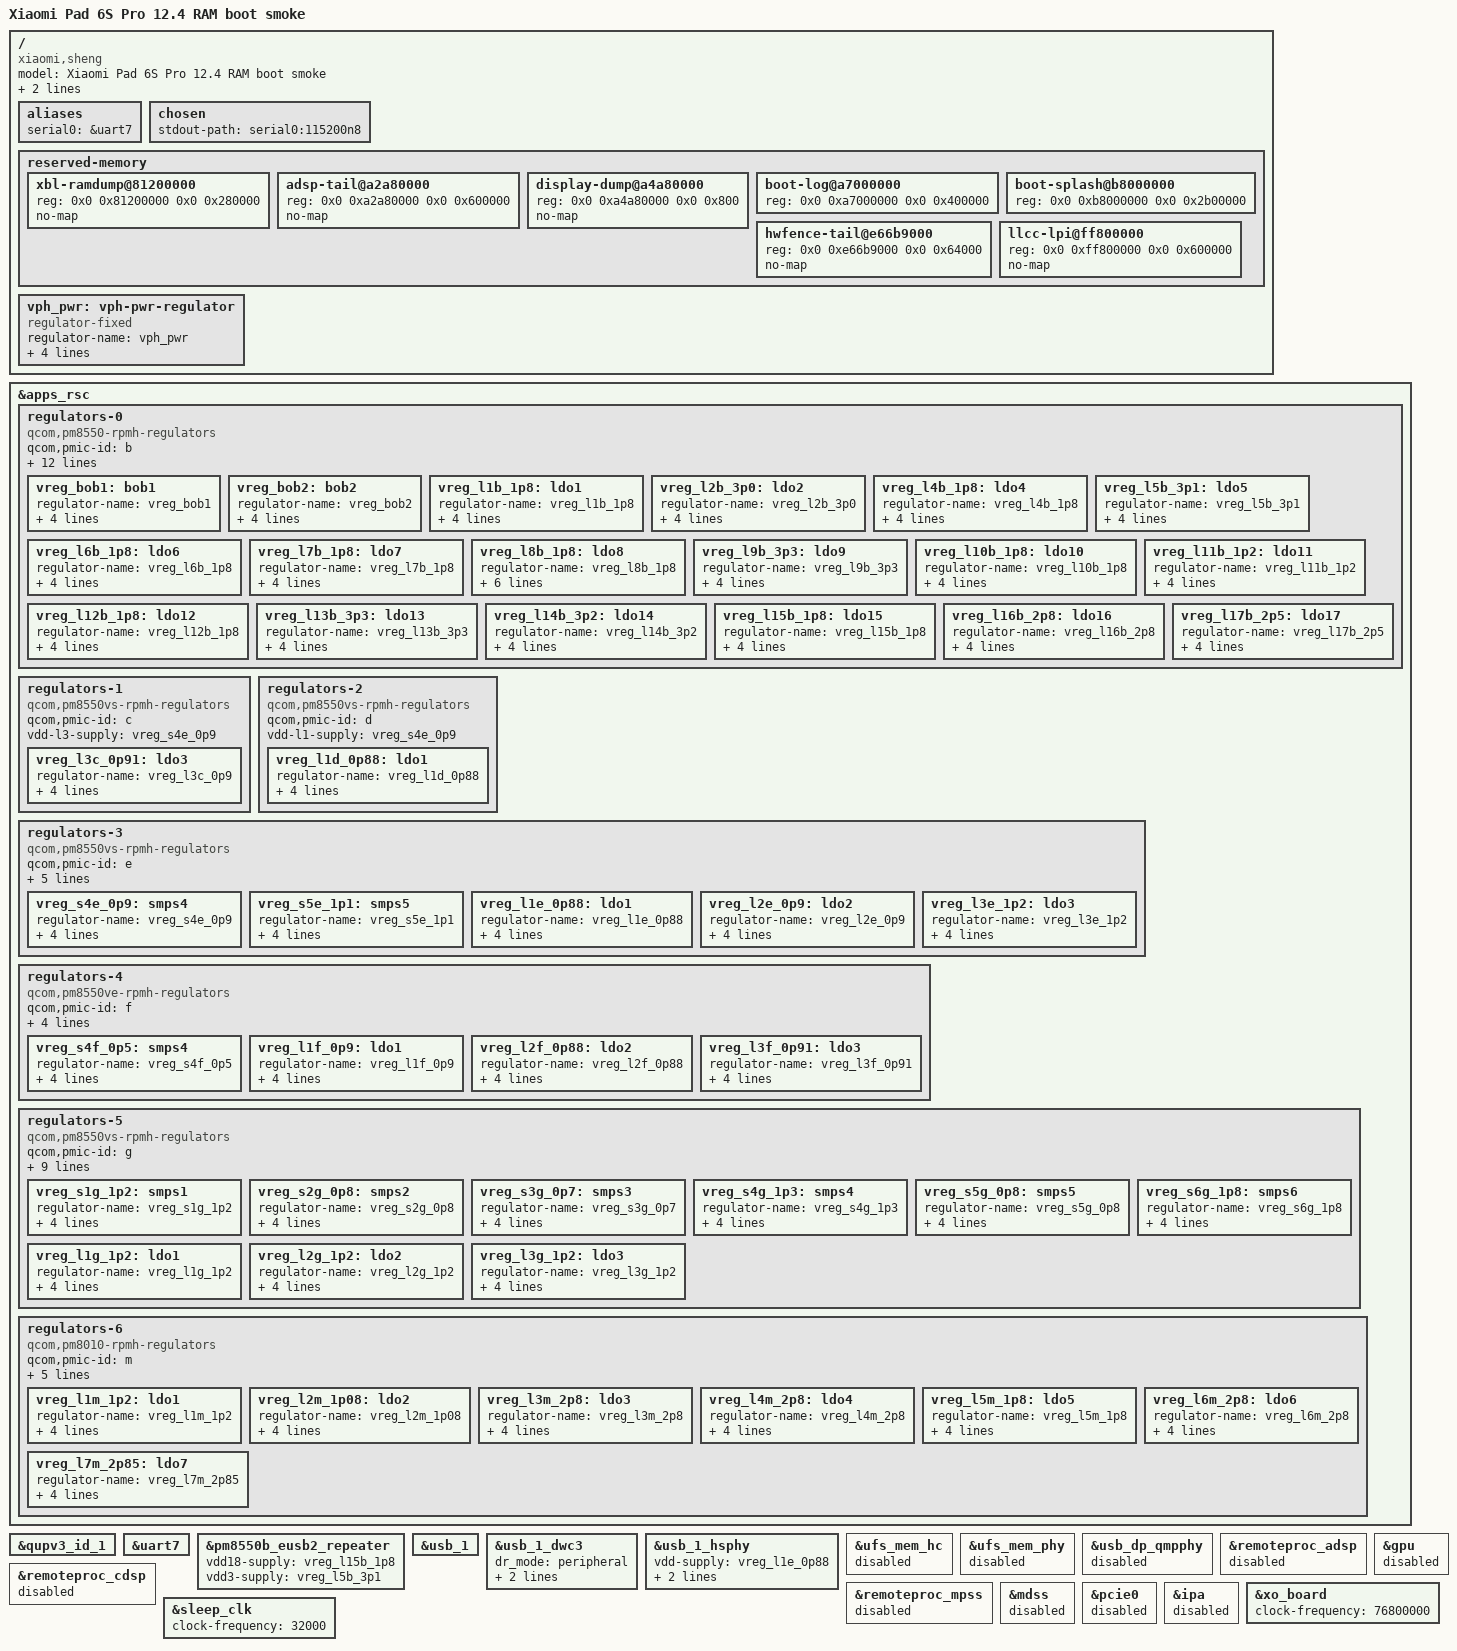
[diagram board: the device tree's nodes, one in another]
// SPDX-License-Identifier: BSD-3-Clause
/*
 * Board regulator data derived from map220v sheng-6.12
 * Copyright (c) 2024, map220v <map220v300@gmail.com>
 */

/dts-v1/;

#include <dt-bindings/arm/qcom,ids.h>
#include <dt-bindings/regulator/qcom,rpmh-regulator.h>
#include "sm8550.dtsi"
#include "pm8010.dtsi"
#include "pm8550.dtsi"
#include "pm8550b.dtsi"
#define PMK8550VE_SID 5
#include "pm8550ve.dtsi"
#include "pm8550vs.dtsi"
#include "pmk8550.dtsi"

/ {
	model = "Xiaomi Pad 6S Pro 12.4 RAM boot smoke";
	compatible = "xiaomi,sheng", "qcom,sm8550";
	qcom,msm-id = <536 0x20000>;
	qcom,board-id = <0x10008 0>;

	aliases {
		serial0 = &uart7;
	};

	chosen {
		stdout-path = "serial0:115200n8";
	};

	/* 保留固件仍占用的内存，避免分配给内核 */
	reserved-memory {
		xbl-ramdump@81200000 {
			reg = <0x0 0x81200000 0x0 0x280000>;
			no-map;
		};

		adsp-tail@a2a80000 {
			reg = <0x0 0xa2a80000 0x0 0x600000>;
			no-map;
		};

		display-dump@a4a80000 {
			reg = <0x0 0xa4a80000 0x0 0x800>;
			no-map;
		};

		boot-log@a7000000 {
			reg = <0x0 0xa7000000 0x0 0x400000>;
		};

		boot-splash@b8000000 {
			reg = <0x0 0xb8000000 0x0 0x2b00000>;
		};

		hwfence-tail@e66b9000 {
			reg = <0x0 0xe66b9000 0x0 0x64000>;
			no-map;
		};

		llcc-lpi@ff800000 {
			reg = <0x0 0xff800000 0x0 0x600000>;
			no-map;
		};
	};

	/* 定义板级主电源输入 */
	vph_pwr: vph-pwr-regulator {
		compatible = "regulator-fixed";
		regulator-name = "vph_pwr";
		regulator-min-microvolt = <3700000>;
		regulator-max-microvolt = <3700000>;

		regulator-always-on;
		regulator-boot-on;
	};
};

/* 使用原板级电压数据供给 USB 及串口依赖 */
&apps_rsc {
	regulators-0 {
		compatible = "qcom,pm8550-rpmh-regulators";
		qcom,pmic-id = "b";

		vdd-bob1-supply = <&vph_pwr>;
		vdd-bob2-supply = <&vph_pwr>;
		vdd-l1-l4-l10-supply = <&vreg_s6g_1p8>;
		vdd-l2-l13-l14-supply = <&vreg_bob1>;
		vdd-l3-supply = <&vreg_s4g_1p3>;
		vdd-l5-l16-supply = <&vreg_bob1>;
		vdd-l6-l7-supply = <&vreg_bob1>;
		vdd-l8-l9-supply = <&vreg_bob1>;
		vdd-l11-supply = <&vreg_s4g_1p3>;
		vdd-l12-supply = <&vreg_s6g_1p8>;
		vdd-l15-supply = <&vreg_s6g_1p8>;
		vdd-l17-supply = <&vreg_bob2>;

		vreg_bob1: bob1 {
			regulator-name = "vreg_bob1";
			regulator-min-microvolt = <3296000>;
			regulator-max-microvolt = <3960000>;
			regulator-initial-mode = <RPMH_REGULATOR_MODE_HPM>;
		};

		/* Xiaomi change for Camera Modules */
		vreg_bob2: bob2 {
			regulator-name = "vreg_bob2";
			regulator-min-microvolt = <2704000>;
			regulator-max-microvolt = <3296000>;
			regulator-initial-mode = <RPMH_REGULATOR_MODE_HPM>;
		};

		vreg_l1b_1p8: ldo1 {
			regulator-name = "vreg_l1b_1p8";
			regulator-min-microvolt = <1800000>;
			regulator-max-microvolt = <1800000>;
			regulator-initial-mode = <RPMH_REGULATOR_MODE_HPM>;
		};

		vreg_l2b_3p0: ldo2 {
			regulator-name = "vreg_l2b_3p0";
			regulator-min-microvolt = <3008000>;
			regulator-max-microvolt = <3008000>;
			regulator-initial-mode = <RPMH_REGULATOR_MODE_HPM>;
		};

		vreg_l4b_1p8: ldo4 {
			regulator-name = "vreg_l4b_1p8";
			regulator-min-microvolt = <1800000>;
			regulator-max-microvolt = <1800000>;
			regulator-initial-mode = <RPMH_REGULATOR_MODE_HPM>;
		};

		vreg_l5b_3p1: ldo5 {
			regulator-name = "vreg_l5b_3p1";
			regulator-min-microvolt = <3104000>;
			regulator-max-microvolt = <3104000>;
			regulator-initial-mode = <RPMH_REGULATOR_MODE_HPM>;
		};

		/* Xiaomi change for Nanosic WN803x */
		vreg_l6b_1p8: ldo6 {
			regulator-name = "vreg_l6b_1p8";
			regulator-min-microvolt = <1800000>;
			regulator-max-microvolt = <1800000>;
			regulator-initial-mode = <RPMH_REGULATOR_MODE_HPM>;
		};

		/* Xiaomi change for Camera Modules */
		vreg_l7b_1p8: ldo7 {
			regulator-name = "vreg_l7b_1p8";
			regulator-min-microvolt = <1800000>;
			regulator-max-microvolt = <1800000>;
			regulator-initial-mode = <RPMH_REGULATOR_MODE_HPM>;
		};

		/* Xiaomi change for Semtech SX9371 */
		vreg_l8b_1p8: ldo8 {
			regulator-name = "vreg_l8b_1p8";
			regulator-min-microvolt = <1800000>;
			regulator-max-microvolt = <1800000>;
			regulator-initial-mode = <RPMH_REGULATOR_MODE_HPM>;
			regulator-always-on;
			regulator-boot-on;
		};

		/* Xiaomi change for FPC1552 */
		vreg_l9b_3p3: ldo9 {
			regulator-name = "vreg_l9b_3p3";
			regulator-min-microvolt = <3296000>;
			regulator-max-microvolt = <3296000>;
			regulator-initial-mode = <RPMH_REGULATOR_MODE_HPM>;
		};

		vreg_l10b_1p8: ldo10 {
			regulator-name = "vreg_l10b_1p8";
			regulator-min-microvolt = <1800000>;
			regulator-max-microvolt = <1800000>;
			regulator-initial-mode = <RPMH_REGULATOR_MODE_HPM>;
		};

		vreg_l11b_1p2: ldo11 {
			regulator-name = "vreg_l11b_1p2";
			regulator-min-microvolt = <1200000>;
			regulator-max-microvolt = <1504000>;
			regulator-initial-mode = <RPMH_REGULATOR_MODE_HPM>;
		};

		vreg_l12b_1p8: ldo12 {
			regulator-name = "vreg_l12b_1p8";
			regulator-min-microvolt = <1800000>;
			regulator-max-microvolt = <1800000>;
			regulator-initial-mode = <RPMH_REGULATOR_MODE_HPM>;
		};

		/* Xiaomi change for Nanosic WN803x */
		vreg_l13b_3p3: ldo13 {
			regulator-name = "vreg_l13b_3p3";
			regulator-min-microvolt = <3296000>;
			regulator-max-microvolt = <3296000>;
			regulator-initial-mode = <RPMH_REGULATOR_MODE_HPM>;
		};

		vreg_l14b_3p2: ldo14 {
			regulator-name = "vreg_l14b_3p2";
			regulator-min-microvolt = <3200000>;
			regulator-max-microvolt = <3200000>;
			regulator-initial-mode = <RPMH_REGULATOR_MODE_HPM>;
		};

		vreg_l15b_1p8: ldo15 {
			regulator-name = "vreg_l15b_1p8";
			regulator-min-microvolt = <1800000>;
			regulator-max-microvolt = <1800000>;
			regulator-initial-mode = <RPMH_REGULATOR_MODE_HPM>;
		};

		vreg_l16b_2p8: ldo16 {
			regulator-name = "vreg_l16b_2p8";
			regulator-min-microvolt = <2800000>;
			regulator-max-microvolt = <2800000>;
			regulator-initial-mode = <RPMH_REGULATOR_MODE_HPM>;
		};

		vreg_l17b_2p5: ldo17 {
			regulator-name = "vreg_l17b_2p5";
			regulator-min-microvolt = <2504000>;
			regulator-max-microvolt = <2504000>;
			regulator-initial-mode = <RPMH_REGULATOR_MODE_HPM>;
		};
	};

	regulators-1 {
		compatible = "qcom,pm8550vs-rpmh-regulators";
		qcom,pmic-id = "c";

		vdd-l3-supply = <&vreg_s4e_0p9>;

		vreg_l3c_0p91: ldo3 {
			regulator-name = "vreg_l3c_0p9";
			regulator-min-microvolt = <880000>;
			regulator-max-microvolt = <912000>;
			regulator-initial-mode = <RPMH_REGULATOR_MODE_HPM>;
		};
	};

	regulators-2 {
		compatible = "qcom,pm8550vs-rpmh-regulators";
		qcom,pmic-id = "d";

		vdd-l1-supply = <&vreg_s4e_0p9>;

		vreg_l1d_0p88: ldo1 {
			regulator-name = "vreg_l1d_0p88";
			regulator-min-microvolt = <880000>;
			regulator-max-microvolt = <920000>;
			regulator-initial-mode = <RPMH_REGULATOR_MODE_HPM>;
		};
	};

	regulators-3 {
		compatible = "qcom,pm8550vs-rpmh-regulators";
		qcom,pmic-id = "e";

		vdd-l1-supply = <&vreg_s4e_0p9>;
		vdd-l2-supply = <&vreg_s4e_0p9>;
		vdd-l3-supply = <&vreg_s4g_1p3>;
		vdd-s4-supply = <&vph_pwr>;
		vdd-s5-supply = <&vph_pwr>;

		vreg_s4e_0p9: smps4 {
			regulator-name = "vreg_s4e_0p9";
			regulator-min-microvolt = <904000>;
			regulator-max-microvolt = <984000>;
			regulator-initial-mode = <RPMH_REGULATOR_MODE_HPM>;
		};

		vreg_s5e_1p1: smps5 {
			regulator-name = "vreg_s5e_1p1";
			regulator-min-microvolt = <1080000>;
			regulator-max-microvolt = <1120000>;
			regulator-initial-mode = <RPMH_REGULATOR_MODE_HPM>;
		};

		vreg_l1e_0p88: ldo1 {
			regulator-name = "vreg_l1e_0p88";
			regulator-min-microvolt = <880000>;
			regulator-max-microvolt = <880000>;
			regulator-initial-mode = <RPMH_REGULATOR_MODE_HPM>;
		};

		vreg_l2e_0p9: ldo2 {
			regulator-name = "vreg_l2e_0p9";
			regulator-min-microvolt = <904000>;
			regulator-max-microvolt = <970000>;
			regulator-initial-mode = <RPMH_REGULATOR_MODE_HPM>;
		};

		vreg_l3e_1p2: ldo3 {
			regulator-name = "vreg_l3e_1p2";
			regulator-min-microvolt = <1200000>;
			regulator-max-microvolt = <1200000>;
			regulator-initial-mode = <RPMH_REGULATOR_MODE_HPM>;
		};
	};

	regulators-4 {
		compatible = "qcom,pm8550ve-rpmh-regulators";
		qcom,pmic-id = "f";

		vdd-l1-supply = <&vreg_s4e_0p9>;
		vdd-l2-supply = <&vreg_s4e_0p9>;
		vdd-l3-supply = <&vreg_s4e_0p9>;
		vdd-s4-supply = <&vph_pwr>;

		vreg_s4f_0p5: smps4 {
			regulator-name = "vreg_s4f_0p5";
			regulator-min-microvolt = <500000>;
			regulator-max-microvolt = <700000>;
			regulator-initial-mode = <RPMH_REGULATOR_MODE_HPM>;
		};

		vreg_l1f_0p9: ldo1 {
			regulator-name = "vreg_l1f_0p9";
			regulator-min-microvolt = <912000>;
			regulator-max-microvolt = <912000>;
			regulator-initial-mode = <RPMH_REGULATOR_MODE_HPM>;
		};

		vreg_l2f_0p88: ldo2 {
			regulator-name = "vreg_l2f_0p88";
			regulator-min-microvolt = <880000>;
			regulator-max-microvolt = <912000>;
			regulator-initial-mode = <RPMH_REGULATOR_MODE_HPM>;
		};

		vreg_l3f_0p91: ldo3 {
			regulator-name = "vreg_l3f_0p91";
			regulator-min-microvolt = <880000>;
			regulator-max-microvolt = <912000>;
			regulator-initial-mode = <RPMH_REGULATOR_MODE_HPM>;
		};
	};

	regulators-5 {
		compatible = "qcom,pm8550vs-rpmh-regulators";
		qcom,pmic-id = "g";

		vdd-l1-supply = <&vreg_s4g_1p3>;
		vdd-l2-supply = <&vreg_s4g_1p3>;
		vdd-l3-supply = <&vreg_s4g_1p3>;
		vdd-s1-supply = <&vph_pwr>;
		vdd-s2-supply = <&vph_pwr>;
		vdd-s3-supply = <&vph_pwr>;
		vdd-s4-supply = <&vph_pwr>;
		vdd-s5-supply = <&vph_pwr>;
		vdd-s6-supply = <&vph_pwr>;

		vreg_s1g_1p2: smps1 {
			regulator-name = "vreg_s1g_1p2";
			regulator-min-microvolt = <1200000>;
			regulator-max-microvolt = <1300000>;
			regulator-initial-mode = <RPMH_REGULATOR_MODE_HPM>;
		};

		vreg_s2g_0p8: smps2 {
			regulator-name = "vreg_s2g_0p8";
			regulator-min-microvolt = <800000>;
			regulator-max-microvolt = <1000000>;
			regulator-initial-mode = <RPMH_REGULATOR_MODE_HPM>;
		};

		/* Xiaomi change for Display Panel */
		vreg_s3g_0p7: smps3 {
			regulator-name = "vreg_s3g_0p7";
			regulator-min-microvolt = <600000>;
			regulator-max-microvolt = <1900000>; //2004000
			regulator-initial-mode = <RPMH_REGULATOR_MODE_HPM>;
		};

		/* Xiaomi change for Camera Modules */
		vreg_s4g_1p3: smps4 {
			regulator-name = "vreg_s4g_1p3";
			regulator-min-microvolt = <1256000>;
			regulator-max-microvolt = <1408000>;
			regulator-initial-mode = <RPMH_REGULATOR_MODE_HPM>;
		};

		vreg_s5g_0p8: smps5 {
			regulator-name = "vreg_s5g_0p8";
			regulator-min-microvolt = <500000>;
			regulator-max-microvolt = <1004000>;
			regulator-initial-mode = <RPMH_REGULATOR_MODE_HPM>;
		};

		vreg_s6g_1p8: smps6 {
			regulator-name = "vreg_s6g_1p8";
			regulator-min-microvolt = <1800000>;
			regulator-max-microvolt = <2000000>;
			regulator-initial-mode = <RPMH_REGULATOR_MODE_HPM>;
		};

		vreg_l1g_1p2: ldo1 {
			regulator-name = "vreg_l1g_1p2";
			regulator-min-microvolt = <1200000>;
			regulator-max-microvolt = <1200000>;
			regulator-initial-mode = <RPMH_REGULATOR_MODE_HPM>;
		};

		vreg_l2g_1p2: ldo2 {
			regulator-name = "vreg_l2g_1p2";
			regulator-min-microvolt = <1200000>;
			regulator-max-microvolt = <1200000>;
			regulator-initial-mode = <RPMH_REGULATOR_MODE_HPM>;
		};

		vreg_l3g_1p2: ldo3 {
			regulator-name = "vreg_l3g_1p2";
			regulator-min-microvolt = <1200000>;
			regulator-max-microvolt = <1200000>;
			regulator-initial-mode = <RPMH_REGULATOR_MODE_HPM>;
		};
	};

	regulators-6 {
		compatible = "qcom,pm8010-rpmh-regulators";
		qcom,pmic-id = "m";

		vdd-l1-l2-supply = <&vreg_s4g_1p3>;
		vdd-l3-l4-supply = <&vreg_bob2>;
		vdd-l5-supply = <&vreg_s6g_1p8>;
		vdd-l6-supply = <&vreg_s6g_1p8>;
		vdd-l7-supply = <&vreg_bob1>;

		/* Xiaomi change for Camera Modules */
		vreg_l1m_1p2: ldo1 {
			regulator-name = "vreg_l1m_1p2";
			regulator-min-microvolt = <1200000>;
			regulator-max-microvolt = <1200000>;
			regulator-initial-mode = <RPMH_REGULATOR_MODE_HPM>;
		};

		/* Xiaomi change for Camera Modules */
		vreg_l2m_1p08: ldo2 {
			regulator-name = "vreg_l2m_1p08";
			regulator-min-microvolt = <1080000>;
			regulator-max-microvolt = <1080000>;
			regulator-initial-mode = <RPMH_REGULATOR_MODE_HPM>;
		};

		vreg_l3m_2p8: ldo3 {
			regulator-name = "vreg_l3m_2p8";
			regulator-min-microvolt = <2800000>;
			regulator-max-microvolt = <2800000>;
			regulator-initial-mode = <RPMH_REGULATOR_MODE_HPM>;
		};

		vreg_l4m_2p8: ldo4 {
			regulator-name = "vreg_l4m_2p8";
			regulator-min-microvolt = <2800000>;
			regulator-max-microvolt = <2800000>;
			regulator-initial-mode = <RPMH_REGULATOR_MODE_HPM>;
		};

		vreg_l5m_1p8: ldo5 {
			regulator-name = "vreg_l5m_1p8";
			regulator-min-microvolt = <1800000>;
			regulator-max-microvolt = <1800000>;
			regulator-initial-mode = <RPMH_REGULATOR_MODE_HPM>;
		};

		/* Xiaomi change for Camera Modules */
		vreg_l6m_2p8: ldo6 {
			regulator-name = "vreg_l6m_2p8";
			regulator-min-microvolt = <2800000>;
			regulator-max-microvolt = <2800000>;
			regulator-initial-mode = <RPMH_REGULATOR_MODE_HPM>;
		};

		/* Xiaomi change for Camera Modules */
		vreg_l7m_2p85: ldo7 {
			regulator-name = "vreg_l7m_2p85";
			regulator-min-microvolt = <2856000>;
			regulator-max-microvolt = <2856000>;
			regulator-initial-mode = <RPMH_REGULATOR_MODE_HPM>;
		};
	};
};

&qupv3_id_1 {
	status = "okay";
};

&uart7 {
	status = "okay";
};

&pm8550b_eusb2_repeater {
	vdd18-supply = <&vreg_l15b_1p8>;
	vdd3-supply = <&vreg_l5b_3p1>;
};

&usb_1 {
	status = "okay";
};

/* 固定为 USB2 外设，避开高速通道方向切换 */
&usb_1_dwc3 {
	dr_mode = "peripheral";
	maximum-speed = "high-speed";
	/delete-property/ usb-role-switch;
	phys = <&usb_1_hsphy>;
	phy-names = "usb2-phy";
	status = "okay";
};

&usb_1_hsphy {
	vdd-supply = <&vreg_l1e_0p88>;
	vdda12-supply = <&vreg_l3e_1p2>;
	phys = <&pm8550b_eusb2_repeater>;
	status = "okay";
};

/* 首轮仅验证内存启动与日志链路 */
&ufs_mem_hc {
	status = "disabled";
};
&ufs_mem_phy {
	status = "disabled";
};
&usb_dp_qmpphy {
	status = "disabled";
};
&remoteproc_adsp {
	status = "disabled";
};
&remoteproc_cdsp {
	status = "disabled";
};
&remoteproc_mpss {
	status = "disabled";
};
&gpu {
	status = "disabled";
};
&mdss {
	status = "disabled";
};
&pcie0 {
	status = "disabled";
};
&ipa {
	status = "disabled";
};

&xo_board {
	clock-frequency = <76800000>;
};
&sleep_clk {
	clock-frequency = <32000>;
};
